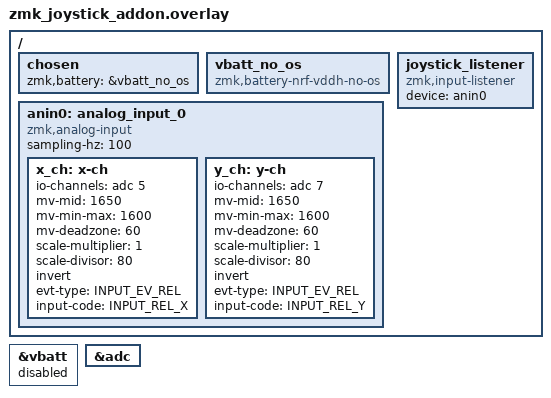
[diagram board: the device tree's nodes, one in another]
/*
 * Copyright (c) 2025 FredForte
 *
 * SPDX-License-Identifier: MIT
 *
 * Composable analog joystick add-on shield for unibody keyboards or the
 * central half of a split keyboard. Does not modify kscan or keymap.
 *
 * Override &x_ch, &y_ch, or &joystick_listener in your keyboard's .overlay
 * to customize ADC channels, calibration, or scroll-layer input processors.
 */

#include <zephyr/dt-bindings/input/input-event-codes.h>
#include <dt-bindings/zmk/input_transform.h>
#include <input/processors.dtsi>

/ {
    chosen {
        zmk,battery = &vbatt_no_os;
    };

    vbatt_no_os: vbatt_no_os {
        compatible = "zmk,battery-nrf-vddh-no-os";
    };
};

&vbatt {
    status = "disabled";
};

&adc {
    status = "okay";
};

/ {
    anin0: analog_input_0 {
        compatible = "zmk,analog-input";
        sampling-hz = <100>;
        x_ch: x-ch {
            io-channels = <&adc 5>; /* nice!nano v2 pin 029 (P0.29 / AIN5) */
            mv-mid = <1650>;
            mv-min-max = <1600>;
            mv-deadzone = <60>;
            scale-multiplier = <1>;
            scale-divisor = <80>;
            invert;
            evt-type = <INPUT_EV_REL>;
            input-code = <INPUT_REL_X>;
        };
        y_ch: y-ch {
            io-channels = <&adc 7>; /* nice!nano v2 pin 031 (P0.31 / AIN7) */
            mv-mid = <1650>;
            mv-min-max = <1600>;
            mv-deadzone = <60>;
            scale-multiplier = <1>;
            scale-divisor = <80>;
            invert;
            evt-type = <INPUT_EV_REL>;
            input-code = <INPUT_REL_Y>;
        };
    };

    joystick_listener: joystick_listener {
        compatible = "zmk,input-listener";
        device = <&anin0>;
    };
};
